# Template register map
Vendor: VendorName Co.Ltd; Series: SeriesName; File version: 1.2
CPU: CM7 r0p1, little endian, MPU, FPU, 4 interrupt priority bits
Registers are 32-bit, read-write, no defined reset value unless marked. A register's access mark holds for its fields unless they carry their own. Offsets are from the block's base; [hi:lo] are bit positions; {n}, {i} and the like mark numbered series.

## FLASH — Embedded Flash Memory
Base 0x400B1000
0x00 ACR — FLASH access control register
  [2:0] LATENCY — FLASH LATENCY[2:0] bit: read latency
0x04 KEYR1 wo — FLASH bank 1 key register
  [31:0] KEY — FLASH KEY[31:0] bit: bank 1 access configuration unlock key
0x08 OPTKEYR wo — FLASH option key register
  [31:0] KEY — FLASH KEY[31:0] bit: unlock key option bytes
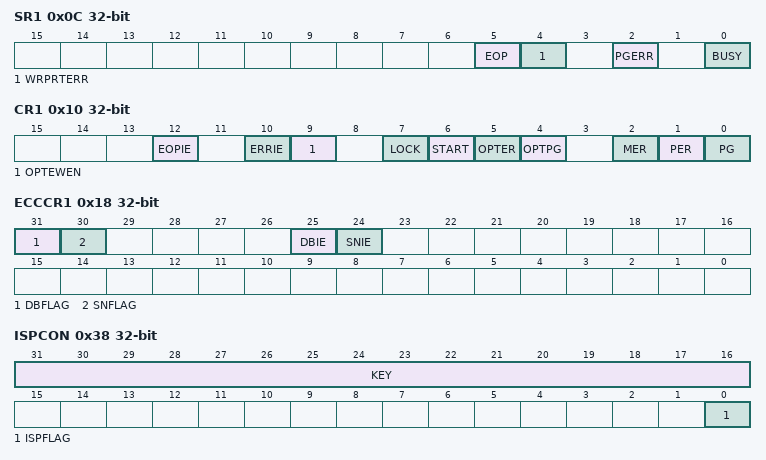
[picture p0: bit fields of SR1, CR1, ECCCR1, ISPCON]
0x0C SR1 — FLASH bank 1 status register
  [5] EOP — FLASH EOP bit: bank 1 end-of-program flag
  [4] WRPRTERR — FLASH WRPRTERR bit: bank 1 write protection error flag
  [2] PGERR — FLASH PGERR bit: bank 1 programming sequence error flag
  [0] BUSY ro — FLASH BUSY bit: bank 1 ongoing program flag
0x10 CR1 — FLASH bank 1 control register
  [12] EOPIE — FLASH EOPIE bit: end of operation interrupt enable
  [10] ERRIE — FLASH ERRIE bit: bank 1 write or erase error interrupt enable bit
  [9] OPTEWEN — FLASH OPTEWEN bit: option bytes write or erase enable control
  [7] LOCK — FLASH LOCK bit: FLASH CR1 lock
  [6] START — FLASH START bit: bank 1 bank or sector erase start control bit
  [5] OPTER — FLASH OPTER bit: option bytes erase mode enable control
  [4] OPTPG — FLASH OPTPG bit: option bytes program mode enable control
  [2] MER — FLASH MER bit: bank 1 mass erase
  [1] PER — FLASH PER bit: page erase
  [0] PG — FLASH PG bit: bank 1 program enable bit
0x14 AR1 — FLASH erase address register 1
  [31:0] ADDR — FLASH ADDR[31:0] bit: address on bank 1
0x18 ECCCR1 — FLASH ECC control register 1
  [31] DBFLAG — FLASH DBFLAG bit: bank 1 ECC circuit check 2 bit error flag
  [30] SNFLAG — FLASH SNFLAG bit: bank 1 ECC circuit check 1 bit error flag
  [25] DBIE — FLASH DBIE bit: bank 1 ECC 2 bit error interrupt configuration
  [24] SNIE — FLASH SNIE bit: bank 1 ECC 1 bit error interrupt enable control
0x1C OBR1 ro — FLASH option byte register 1
  [7] BANKSWAP — FLASH BANKSWAP bit: bank swap status
0x20 WRPR11 ro — FLASH bank 1 write or erase protect register 1
  [31:0] WRP — FLASH WRP[31:0] bit: bank 1 write or erase protect sector from 0 to 127
0x24 WRPR12 ro — FLASH bank 1 write or erase protect register 2
  [31:0] WRP — FLASH WRP[31:0] bit: bank 1 write or erase protect sector from 128 to 255
0x28 WRPR13 ro — FLASH bank 1 write or erase protect register 3
  [31:0] WRP — FLASH WRP[31:0] bit: bank 1 write or erase protect sector from 256 to 383
0x2C WRPR14 ro — FLASH bank 1 write or erase protect register 4
  [31:0] WRP — FLASH WRP[31:0] bit: bank 1 write or erase protect sector from 384 to 511
0x38 ISPCON — FLASH ISP control register
  [31:16] KEY wo — FLASH KEY[15:0] bit: only when 0x5A69 is written can this register be written
  [0] ISPFLAG — FLASH ISPFLAG bit: the condition for executing BootLoader
0x104 KEYR2 wo — FLASH key register for bank 2
  [31:0] KEY — FLASH KEY[31:0] bit: bank 2 access configuration unlock key
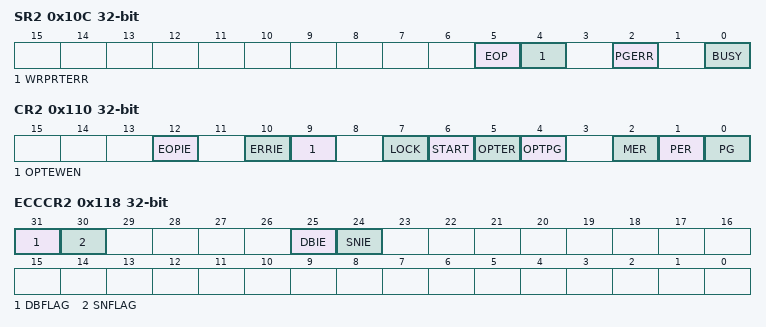
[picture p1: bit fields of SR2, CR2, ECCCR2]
0x10C SR2 — FLASH status register for bank 2
  [5] EOP — FLASH EOP bit: bank 2 end-of-program flag
  [4] WRPRTERR — FLASH WRPRTERR bit: bank 2 write protection error flag
  [2] PGERR — FLASH PGERR bit: bank 2 programming error flag
  [0] BUSY ro — FLASH BUSY bit: bank 2 ongoing program flag
0x110 CR2 — FLASH control register for bank 2
  [12] EOPIE — FLASH EOPIE bit: end of operation interrupt enable
  [10] ERRIE — FLASH ERRIE bit: bank 2 write or erase error interrupt enable bit
  [9] OPTEWEN — FLASH OPTEWEN bit: option bytes write or erase enable control
  [7] LOCK — FLASH LOCK bit: FLASH CR2 lock
  [6] START — FLASH START bit: bank 2 bank or sector erase start control bit
  [5] OPTER — FLASH OPTER bit: option bytes erase mode enable control
  [4] OPTPG — FLASH OPTPG bit: option bytes program mode enable control
  [2] MER — FLASH MER bit: bank 2 mass erase
  [1] PER — FLASH PER bit: page erase
  [0] PG — FLASH PG bit: bank 2 program enable bit
0x114 AR2 — FLASH erase address register 2
  [31:0] ADDR — FLASH ADDR[31:0] bit: address on bank 2
0x118 ECCCR2 — FLASH ECC control register 2
  [31] DBFLAG — FLASH DBFLAG bit: bank 2 ECC circuit check 2 bit error flag
  [30] SNFLAG — FLASH SNFLAG bit: bank 2 ECC circuit check 1 bit error flag
  [25] DBIE — FLASH DBIE bit: bank 2 ECC 2 bit error interrupt configuration
  [24] SNIE — FLASH SNIE bit: bank 2 ECC 1 bit error interrupt enable control
{0xCC+4i} WRPR{i} ro (i=21..24) — FLASH bank 2 write or erase protect register {i-20}
  [31:0] WRP — FLASH WRP[31:0] bit: bank 2 write or erase protect sector from {128i-2688} to {128i-2561}
0x130 ECCADDR ro — FLASH ECC error address register
  [31:0] ADDR — FLASH ADDR[31:0] bit: ECC error address
